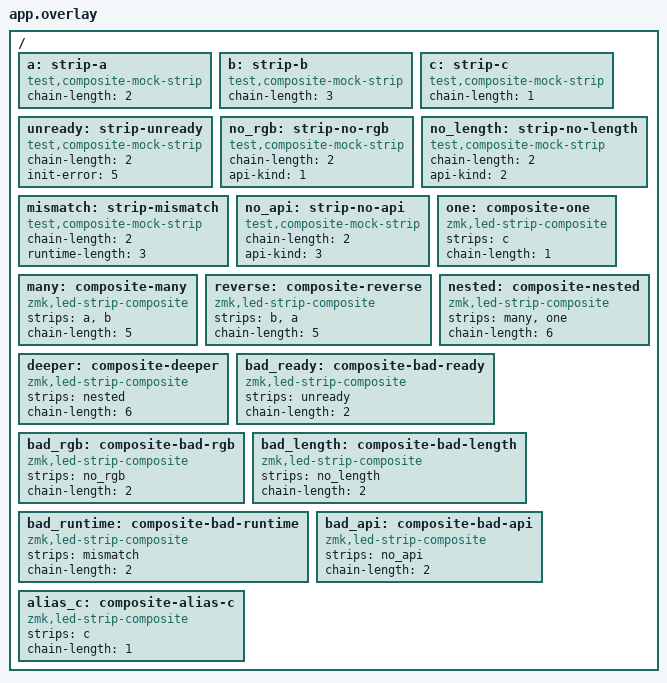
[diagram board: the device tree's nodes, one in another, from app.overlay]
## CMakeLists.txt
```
# Copyright (c) 2026 The ZMK Contributors
# SPDX-License-Identifier: MIT

cmake_minimum_required(VERSION 3.20.0)
list(APPEND DTS_ROOT ${CMAKE_CURRENT_SOURCE_DIR})
find_package(Zephyr REQUIRED HINTS $ENV{ZEPHYR_BASE})
project(led_strip_composite)
target_sources(app PRIVATE src/mock_strip.c src/main.c)
```

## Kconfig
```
# Copyright (c) 2026 The ZMK Contributors
# SPDX-License-Identifier: MIT

mainmenu "Composite LED strip tests"

source "Kconfig.zephyr"

config COMPOSITE_TEST_RGB_SCRATCH
    bool "Exercise padded led_rgb layout"
    select LED_STRIP_RGB_SCRATCH
```

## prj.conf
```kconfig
CONFIG_ZTEST=y
CONFIG_LED_STRIP=y
CONFIG_ASSERT=y
CONFIG_MAIN_STACK_SIZE=4096
CONFIG_TEST_RANDOM_GENERATOR=y
```

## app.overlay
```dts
/*
 * Copyright (c) 2026 The ZMK Contributors
 *
 * SPDX-License-Identifier: MIT
 */

/ {
    a: strip-a { compatible = "test,composite-mock-strip"; chain-length = <2>; };
    b: strip-b { compatible = "test,composite-mock-strip"; chain-length = <3>; };
    c: strip-c { compatible = "test,composite-mock-strip"; chain-length = <1>; };
    unready: strip-unready { compatible = "test,composite-mock-strip"; chain-length = <2>; init-error = <5>; };
    no_rgb: strip-no-rgb { compatible = "test,composite-mock-strip"; chain-length = <2>; api-kind = <1>; };
    no_length: strip-no-length { compatible = "test,composite-mock-strip"; chain-length = <2>; api-kind = <2>; };
    mismatch: strip-mismatch { compatible = "test,composite-mock-strip"; chain-length = <2>; runtime-length = <3>; };
    no_api: strip-no-api { compatible = "test,composite-mock-strip"; chain-length = <2>; api-kind = <3>; };

    one: composite-one { compatible = "zmk,led-strip-composite"; strips = <&c>; chain-length = <1>; };
    many: composite-many { compatible = "zmk,led-strip-composite"; strips = <&a &b>; chain-length = <5>; };
    reverse: composite-reverse { compatible = "zmk,led-strip-composite"; strips = <&b &a>; chain-length = <5>; };
    nested: composite-nested { compatible = "zmk,led-strip-composite"; strips = <&many &one>; chain-length = <6>; };
    deeper: composite-deeper { compatible = "zmk,led-strip-composite"; strips = <&nested>; chain-length = <6>; };

    bad_ready: composite-bad-ready { compatible = "zmk,led-strip-composite"; strips = <&unready>; chain-length = <2>; };
    bad_rgb: composite-bad-rgb { compatible = "zmk,led-strip-composite"; strips = <&no_rgb>; chain-length = <2>; };
    bad_length: composite-bad-length { compatible = "zmk,led-strip-composite"; strips = <&no_length>; chain-length = <2>; };
    bad_runtime: composite-bad-runtime { compatible = "zmk,led-strip-composite"; strips = <&mismatch>; chain-length = <2>; };
    bad_api: composite-bad-api { compatible = "zmk,led-strip-composite"; strips = <&no_api>; chain-length = <2>; };
    alias_c: composite-alias-c { compatible = "zmk,led-strip-composite"; strips = <&c>; chain-length = <1>; };
};
```

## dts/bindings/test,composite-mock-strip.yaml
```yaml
# Copyright (c) 2026 The ZMK Contributors
# SPDX-License-Identifier: MIT

description: Instrumented LED strip for composite driver tests
compatible: "test,composite-mock-strip"
include: base.yaml
properties:
  chain-length:
    type: int
    required: true
  runtime-length:
    type: int
    default: 0
    description: Nonzero overrides the length callback result.
  init-error:
    type: int
    default: 0
    description: Positive errno returned negatively by init.
  api-kind:
    type: int
    default: 0
    enum: [0, 1, 2, 3]
    description: 0 is complete, 1 omits update_rgb, 2 omits length, 3 has no API.
```

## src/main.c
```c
/*
 * Copyright (c) 2026 The ZMK Contributors
 *
 * SPDX-License-Identifier: MIT
 */

#include <errno.h>
#include <string.h>
#include <zephyr/ztest.h>
#include "mock_strip.h"

BUILD_ASSERT(IS_ENABLED(CONFIG_LED_STRIP_COMPOSITE));
BUILD_ASSERT(!IS_ENABLED(CONFIG_KEYPAW_RGB_MATRIX));

#define DEV(label) DEVICE_DT_GET(DT_NODELABEL(label))

static const struct device *const leaves[] = {DEV(a), DEV(b), DEV(c)};
static const size_t lengths[] = {2, 3, 1};

static void before(void *fixture)
{
    ARG_UNUSED(fixture);
    mock_reset();
}

static void colors(struct led_rgb *pixels, size_t count)
{
    memset(pixels, 0, count * sizeof(*pixels));
    for (size_t i = 0; i < count; i++) {
        pixels[i].r = i + 1;
        pixels[i].g = i + 31;
        pixels[i].b = i + 61;
    }
}

static void call_is(size_t index, const struct device *dev, struct led_rgb *ptr,
                    size_t count, const struct led_rgb *expected)
{
    zassert_true(index < mock_call_count);
    const struct mock_call *call = &mock_calls[index];

    zassert_equal(call->dev, dev, "wrong child at call %zu", index);
    zassert_equal(call->pixels, ptr, "driver must pass the caller's slice");
    zassert_equal(call->count, count);
    zassert_mem_equal(call->before, expected, count * sizeof(*expected));
}

static void check_prefix(const struct device *dev, size_t total)
{
    for (size_t prefix = 0; prefix <= total; prefix++) {
        struct led_rgb pixels[8], expected[8];
        size_t offset = 0, calls = 0;

        mock_reset();
        colors(pixels, ARRAY_SIZE(pixels));
        memcpy(expected, pixels, sizeof(pixels));
        for (size_t i = 0; i < ARRAY_SIZE(leaves); i++) {
            ((struct mock_strip_data *)leaves[i]->data)->mutate = true;
        }
        zassert_ok(led_strip_update_rgb(dev, pixels, prefix));
        for (size_t i = 0; i < ARRAY_SIZE(leaves) && offset < prefix; i++) {
            size_t count = MIN(lengths[i], prefix - offset);

            call_is(calls++, leaves[i], &pixels[offset], count, &expected[offset]);
            for (size_t j = offset; j < offset + count; j++) {
                zassert_equal(pixels[j].r, 0xa5);
                zassert_equal(pixels[j].g, 0xa5);
                zassert_equal(pixels[j].b, 0xa5);
            }
            offset += count;
        }
        zassert_equal(mock_call_count, calls);
        zassert_mem_equal(&pixels[prefix], &expected[prefix],
                          (ARRAY_SIZE(pixels) - prefix) * sizeof(pixels[0]));
    }
}

ZTEST(composite, test_lengths_and_dependency_initialization)
{
    const struct device *const devices[] = {
        DEV(one), DEV(many), DEV(reverse), DEV(nested), DEV(deeper), DEV(alias_c),
    };
    const size_t totals[] = {1, 5, 5, 6, 6, 1};

    for (size_t i = 0; i < ARRAY_SIZE(devices); i++) {
        zassert_true(device_is_ready(devices[i]), "%s not ready", devices[i]->name);
        zassert_equal(devices[i]->state->init_res, 0);
        zassert_equal(led_strip_length(devices[i]), totals[i]);
    }
}

ZTEST(composite, test_single_and_ordered_instances)
{
    struct led_rgb pixels[5], expected[5];

    colors(pixels, ARRAY_SIZE(pixels));
    memcpy(expected, pixels, sizeof(pixels));
    zassert_ok(led_strip_update_rgb(DEV(one), pixels, 1));
    call_is(0, DEV(c), pixels, 1, expected);
    zassert_equal(mock_call_count, 1);
    mock_reset();
    zassert_ok(led_strip_update_rgb(DEV(reverse), pixels, 5));
    call_is(0, DEV(b), pixels, 3, expected);
    call_is(1, DEV(a), pixels + 3, 2, expected + 3);
    zassert_equal(mock_call_count, 2);
}

ZTEST(composite, test_every_prefix_and_mutating_children)
{
    check_prefix(DEV(many), 5);
    check_prefix(DEV(nested), 6);
    check_prefix(DEV(deeper), 6);
}

ZTEST(composite, test_argument_errors_and_channels)
{
    const struct device *dev = DEV(many);
    struct led_rgb pixels[8];
    uint8_t channels[3] = {1, 2, 3};
    size_t length = led_strip_length(dev);

    colors(pixels, ARRAY_SIZE(pixels));
    zassert_ok(led_strip_update_rgb(dev, NULL, 0));
    zassert_ok(led_strip_update_rgb(dev, pixels, 0));
    zassert_equal(led_strip_update_rgb(dev, NULL, 1), -EINVAL);
    zassert_equal(led_strip_update_rgb(dev, pixels, length + 1), -ERANGE);
    zassert_equal(led_strip_update_rgb(dev, NULL, length + 1), -ERANGE);
    zassert_equal(led_strip_update_channels(dev, channels, 3), -ENOSYS);
    zassert_equal(mock_call_count, 0);
}

ZTEST(composite, test_first_failure_and_continued_dispatch)
{
    struct led_rgb pixels[6], expected[6];
    const int errors[] = {-EIO, -ETIMEDOUT, -EBUSY};

    for (size_t first = 0; first < ARRAY_SIZE(leaves); first++) {
        mock_reset();
        colors(pixels, ARRAY_SIZE(pixels));
        memcpy(expected, pixels, sizeof(pixels));
        for (size_t i = 0; i < ARRAY_SIZE(leaves); i++) {
            struct mock_strip_data *data = leaves[i]->data;

            data->result = i >= first ? errors[i] : 0;
            data->mutate = true;
        }
        zassert_equal(led_strip_update_rgb(DEV(deeper), pixels, 6), errors[first]);
        zassert_equal(mock_call_count, 3);
        call_is(0, DEV(a), pixels, 2, expected);
        call_is(1, DEV(b), pixels + 2, 3, expected + 2);
        call_is(2, DEV(c), pixels + 5, 1, expected + 5);
    }
}

ZTEST(composite, test_only_negative_results_are_errors)
{
    struct led_rgb pixels[6];

    colors(pixels, ARRAY_SIZE(pixels));
    ((struct mock_strip_data *)DEV(a)->data)->result = 1;
    ((struct mock_strip_data *)DEV(b)->data)->result = -EIO;
    zassert_equal(led_strip_update_rgb(DEV(nested), pixels, 6), -EIO);
    zassert_equal(mock_call_count, 3);
    mock_reset();
    ((struct mock_strip_data *)DEV(a)->data)->result = 1;
    zassert_ok(led_strip_update_rgb(DEV(nested), pixels, 6));
    zassert_equal(mock_call_count, 3);
}

ZTEST(composite, test_failure_at_partial_boundary)
{
    struct led_rgb pixels[6], expected[6];

    colors(pixels, ARRAY_SIZE(pixels));
    memcpy(expected, pixels, sizeof(pixels));
    ((struct mock_strip_data *)DEV(a)->data)->result = -EIO;
    ((struct mock_strip_data *)DEV(a)->data)->mutate = true;
    ((struct mock_strip_data *)DEV(b)->data)->result = -EBUSY;
    zassert_equal(led_strip_update_rgb(DEV(nested), pixels, 3), -EIO);
    zassert_equal(mock_call_count, 2);
    call_is(0, DEV(a), pixels, 2, expected);
    call_is(1, DEV(b), pixels + 2, 1, expected + 2);
    zassert_mem_equal(pixels + 3, expected + 3, 3 * sizeof(pixels[0]));
}

ZTEST(composite, test_runtime_init_errors)
{
    const struct device *const devices[] = {
        DEV(bad_ready), DEV(bad_rgb), DEV(bad_length), DEV(bad_runtime), DEV(bad_api),
    };
    const int errors[] = {ENODEV, ENOTSUP, ENOTSUP, EINVAL, ENOTSUP};

    zassert_false(device_is_ready(DEV(unready)));
    zassert_equal(DEV(unready)->state->init_res, EIO);
    zassert_true(device_is_ready(DEV(no_rgb)));
    zassert_true(device_is_ready(DEV(no_length)));
    zassert_true(device_is_ready(DEV(mismatch)));
    zassert_true(device_is_ready(DEV(no_api)));
    for (size_t i = 0; i < ARRAY_SIZE(devices); i++) {
        zassert_true(devices[i]->state->initialized);
        zassert_false(device_is_ready(devices[i]), "%s unexpectedly ready", devices[i]->name);
        zassert_equal(devices[i]->state->init_res, errors[i], "%s", devices[i]->name);
    }
    zassert_equal(mock_call_count, 0);
}

ZTEST_SUITE(composite, NULL, NULL, before, NULL, NULL);
```

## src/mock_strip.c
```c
/*
 * Copyright (c) 2026 The ZMK Contributors
 *
 * SPDX-License-Identifier: MIT
 */

#define DT_DRV_COMPAT test_composite_mock_strip

#include <string.h>
#include <zephyr/ztest.h>
#include "mock_strip.h"

struct mock_strip_config {
    size_t length;
    int init_error;
};

struct mock_call mock_calls[MOCK_MAX_CALLS];
size_t mock_call_count;

static int mock_update(const struct device *dev, struct led_rgb *pixels, size_t count)
{
    struct mock_strip_data *data = dev->data;

    zassert_true(mock_call_count < MOCK_MAX_CALLS);
    zassert_true(count <= MOCK_MAX_PIXELS);
    struct mock_call *call = &mock_calls[mock_call_count++];

    call->dev = dev;
    call->pixels = pixels;
    call->count = count;
    if (count) {
        memcpy(call->before, pixels, count * sizeof(*pixels));
        if (data->mutate) {
            memset(pixels, 0xa5, count * sizeof(*pixels));
        }
    }
    return data->result;
}

static size_t mock_length(const struct device *dev)
{
    const struct mock_strip_config *config = dev->config;

    return config->length;
}

static int mock_init(const struct device *dev)
{
    const struct mock_strip_config *config = dev->config;

    return -config->init_error;
}

static const struct led_strip_driver_api mock_api_0 = {
    .update_rgb = mock_update,
    .length = mock_length,
};
static const struct led_strip_driver_api mock_api_1 = {
    .length = mock_length,
};
static const struct led_strip_driver_api mock_api_2 = {
    .update_rgb = mock_update,
};

#define MOCK_API_0 (&mock_api_0)
#define MOCK_API_1 (&mock_api_1)
#define MOCK_API_2 (&mock_api_2)
#define MOCK_API_3 NULL

#define MOCK_DEFINE(inst)                                                        \
    static struct mock_strip_data mock_data_##inst;                               \
    static const struct mock_strip_config mock_config_##inst = {                  \
        .length = DT_INST_PROP(inst, runtime_length) ?                            \
                      DT_INST_PROP(inst, runtime_length) :                       \
                      DT_INST_PROP(inst, chain_length),                          \
        .init_error = DT_INST_PROP(inst, init_error),                             \
    };                                                                           \
    DEVICE_DT_INST_DEFINE(inst, mock_init, NULL, &mock_data_##inst,                \
                          &mock_config_##inst, POST_KERNEL, 50,                   \
                          UTIL_CAT(MOCK_API_, DT_INST_PROP(inst, api_kind)));

DT_INST_FOREACH_STATUS_OKAY(MOCK_DEFINE)

#define MOCK_RESET(inst) memset(&mock_data_##inst, 0, sizeof(mock_data_##inst));

void mock_reset(void)
{
    mock_call_count = 0;
    memset(mock_calls, 0, sizeof(mock_calls));
    DT_INST_FOREACH_STATUS_OKAY(MOCK_RESET)
}
```

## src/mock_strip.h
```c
/*
 * Copyright (c) 2026 The ZMK Contributors
 *
 * SPDX-License-Identifier: MIT
 */

#ifndef COMPOSITE_MOCK_STRIP_H
#define COMPOSITE_MOCK_STRIP_H

#include <zephyr/drivers/led_strip.h>

#define MOCK_MAX_PIXELS 16
#define MOCK_MAX_CALLS 16

struct mock_strip_data {
    int result;
    bool mutate;
};

struct mock_call {
    const struct device *dev;
    struct led_rgb *pixels;
    size_t count;
    struct led_rgb before[MOCK_MAX_PIXELS];
};

extern struct mock_call mock_calls[MOCK_MAX_CALLS];
extern size_t mock_call_count;
void mock_reset(void);

#endif
```
